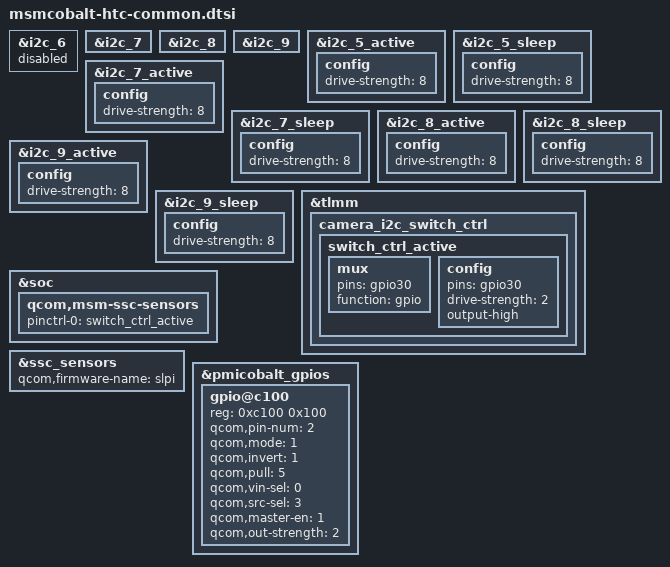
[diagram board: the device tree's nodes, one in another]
/*
 * msmcobalt-htc-common: common configs of msmcobalt HTC projects
 */

#include "msmcobalt-touch-muskie.dtsi"
#include "msmcobalt-key-muskie.dtsi"
#include "msmcobalt-audio-muskie.dtsi"
#include "msmcobalt-htc-fingerprint-muskie.dtsi"

&i2c_6 {
	status = "disabled";
};

&i2c_7 {
	status = "okay";
};

&i2c_8 {
	status = "okay";
};

&i2c_9 {
	status = "okay";
};

&i2c_5_active {
	config {
		drive-strength = <8>;
	};
};
&i2c_5_sleep {
	config {
		drive-strength = <8>;
	};
};

&i2c_7_active {
	config {
		drive-strength = <8>;
	};
};
&i2c_7_sleep {
	config {
		drive-strength = <8>;
	};
};

&i2c_8_active {
	config {
		drive-strength = <8>;
	};
};
&i2c_8_sleep {
	config {
		drive-strength = <8>;
	};
};

&i2c_9_active {
	config {
		drive-strength = <8>;
	};
};
&i2c_9_sleep {
	config {
		drive-strength = <8>;
	};
};

&tlmm {
	camera_i2c_switch_ctrl {
		switch_ctrl_active: switch_ctrl_active {
			mux {
				pins = "gpio30";
				function = "gpio";
			};

			config {
				pins = "gpio30";
				drive-strength = <2>;
				output-high;
			};
		};
	};
};


&soc {
	qcom,msm-ssc-sensors {
		pinctrl-names = "default";
		pinctrl-0 = <&switch_ctrl_active>;
	};
};

&ssc_sensors {
	qcom,firmware-name = "slpi";
};

&pmicobalt_gpios {
	gpio@c100 {
		reg = <0xc100 0x100>;
		qcom,pin-num = <2>;
		status = "okay";
		qcom,mode = <1>; // Digital output
		qcom,invert = <1>;
		qcom,pull = <5>; // No Pull
		qcom,vin-sel = <0>; // 1.8 V, VIN0
		qcom,src-sel = <3>;
		qcom,master-en = <1>; // enable GPIO
		qcom,out-strength = <2>; // Output strength medium
	};
};
